# STM32F373 register map
File version: 1.7
CPU: CM4 r1p0, little endian, MPU, FPU, 4 interrupt priority bits
Registers are 32-bit, read-write, reset 0x0 unless marked. A register's access mark holds for its fields unless they carry their own. Offsets are from the block's base; [hi:lo] are bit positions.

## CEC — HDMI-CEC controller
Base 0x40007800
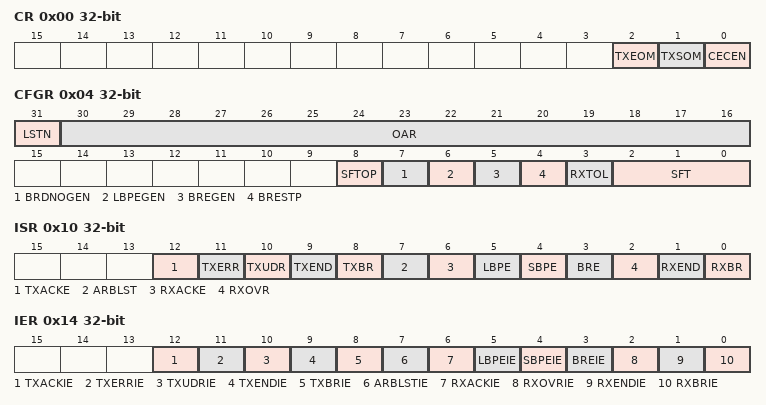
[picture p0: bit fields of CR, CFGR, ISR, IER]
0x00 CR — control register
  [2] TXEOM — Tx End Of Message
  [1] TXSOM — Tx start of message
  [0] CECEN — CEC Enable
0x04 CFGR — configuration register
  [31] LSTN — Listen mode
  [30:16] OAR — Own Address
  [8] SFTOP — SFT Option Bit
  [7] BRDNOGEN — Avoid Error-Bit Generation in Broadcast
  [6] LBPEGEN — Generate Error-Bit on Long Bit Period Error
  [5] BREGEN — Generate error-bit on bit rising error
  [4] BRESTP — Rx-stop on bit rising error
  [3] RXTOL — Rx-Tolerance
  [2:0] SFT — Signal Free Time
0x08 TXDR wo — Tx data register
  [7:0] TXD — Tx Data register
0x0C RXDR ro — Rx Data Register
  [7:0] RXDR — CEC Rx Data Register
0x10 ISR — Interrupt and Status Register
  [12] TXACKE — Tx-Missing acknowledge error
  [11] TXERR — Tx-Error
  [10] TXUDR — Tx-Buffer Underrun
  [9] TXEND — End of Transmission
  [8] TXBR — Tx-Byte Request
  [7] ARBLST — Arbitration Lost
  [6] RXACKE — Rx-Missing Acknowledge
  [5] LBPE — Rx-Long Bit Period Error
  [4] SBPE — Rx-Short Bit period error
  [3] BRE — Rx-Bit rising error
  [2] RXOVR — Rx-Overrun
  [1] RXEND — End Of Reception
  [0] RXBR — Rx-Byte Received
0x14 IER — interrupt enable register
  [12] TXACKIE — Tx-Missing Acknowledge Error Interrupt Enable
  [11] TXERRIE — Tx-Error Interrupt Enable
  [10] TXUDRIE — Tx-Underrun interrupt enable
  [9] TXENDIE — Tx-End of message interrupt enable
  [8] TXBRIE — Tx-Byte Request Interrupt Enable
  [7] ARBLSTIE — Arbitration Lost Interrupt Enable
  [6] RXACKIE — Rx-Missing Acknowledge Error Interrupt Enable
  [5] LBPEIE — Long Bit Period Error Interrupt Enable
  [4] SBPEIE — Short Bit Period Error Interrupt Enable
  [3] BREIE — Bit Rising Error Interrupt Enable
  [2] RXOVRIE — Rx-Buffer Overrun Interrupt Enable
  [1] RXENDIE — End Of Reception Interrupt Enable
  [0] RXBRIE — Rx-Byte Received Interrupt Enable

## PWR — Power control
Base 0x40007000
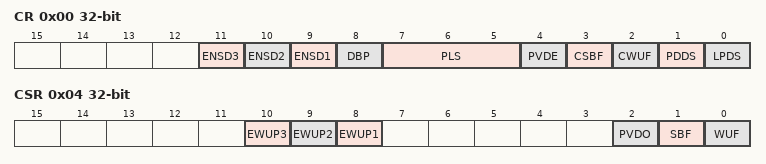
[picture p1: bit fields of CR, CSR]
0x00 CR — power control register
  [11] ENSD3 — ENable SD3 ADC
  [10] ENSD2 — ENable SD2 ADC
  [9] ENSD1 — ENable SD1 ADC
  [8] DBP — Disable backup domain write protection
  [7:5] PLS — PVD level selection
  [4] PVDE — Power voltage detector enable
  [3] CSBF — Clear standby flag
  [2] CWUF — Clear wakeup flag
  [1] PDDS — Power down deepsleep
  [0] LPDS — Low-power deep sleep
0x04 CSR access per field — power control/status register
  [10] EWUP3 rw — Enable WKUP3 pin
  [9] EWUP2 rw — Enable WKUP2 pin
  [8] EWUP1 rw — Enable WKUP1 pin
  [2] PVDO ro — PVD output
  [1] SBF ro — Standby flag
  [0] WUF ro — Wakeup flag

## IWDG — Independent watchdog
Base 0x40003000
0x00 KR 16-bit wo — Key register
  [15:0] KEY — Key value
    0x5555=Unlock (Enable access to PR, RLR and WINR registers); 0xAAAA=Feed watchdog with RLR register value; 0xCCCC=Start the watchdog
0x04 PR 16-bit — Prescaler register
  [2:0] PR — Prescaler divider
    0=DivideBy4 (Divider /4); 1=DivideBy8 (Divider /8); 2=DivideBy16 (Divider /16); 3=DivideBy32 (Divider /32); 4=DivideBy64 (Divider /64); 5=DivideBy128 (Divider /128); other=DivideBy256 (Divider /256)
0x08 RLR 16-bit reset 0xFFF — Reload register
  [11:0] RL — Watchdog counter reload value
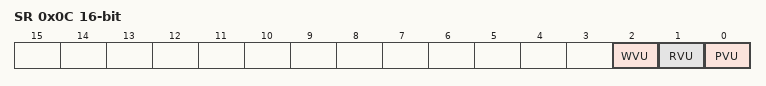
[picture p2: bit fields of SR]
0x0C SR 16-bit ro — Status register
  [2] WVU — Watchdog counter window value update
  [1] RVU — Watchdog counter reload value update
  [0] PVU — Watchdog prescaler value update
0x10 WINR 16-bit reset 0xFFF — Window register
  [11:0] WIN — Watchdog counter window value

## WWDG — Window watchdog
Base 0x40002C00
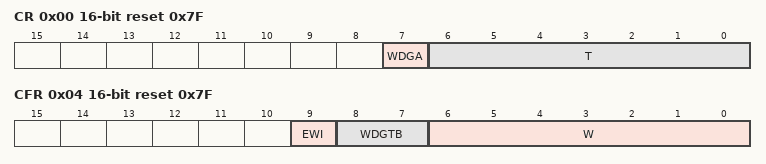
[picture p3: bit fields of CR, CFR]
0x00 CR 16-bit reset 0x7F — Control register
  [7] WDGA — Activation bit
    0=Disabled (Watchdog disabled); 1=Enabled (Watchdog enabled)
  [6:0] T — 7-bit counter
0x04 CFR 16-bit reset 0x7F — Configuration register
  [9] EWI — Early wakeup interrupt
    on write: 1=Enable (interrupt occurs whenever the counter reaches the value 0x40)
  [8:7] WDGTB — Timer base
    0=Div1 (Counter clock (PCLK1 div 4096) div 1); 1=Div2 (Counter clock (PCLK1 div 4096) div 2); 2=Div4 (Counter clock (PCLK1 div 4096) div 4); 3=Div8 (Counter clock (PCLK1 div 4096) div 8)
  [6:0] W — 7-bit window value
0x08 SR 16-bit — Status register
  [0] EWIF write-0-clears — Early wakeup interrupt flag
    on read: 0=Finished (The EWI Interrupt Service Routine has been serviced); 1=Pending (The EWI Interrupt Service Routine has been triggered) | on write: 0=Finished (The EWI Interrupt Service Routine has been serviced)
